# haltium_radiocore register map
Vendor: Nordic Semiconductor; Series: nRFHaltium; File version: 1
CPU: CM33 r0p4, little endian, MPU, FPU, 3 interrupt priority bits, 480 interrupts
Registers are 32-bit, read-write, reset 0x0 unless marked. A register's access mark holds for its fields unless they carry their own. Offsets are from the block's base; [hi:lo] are bit positions; lines under a group give offsets from that group; {n}, {i} and the like mark numbered series.

## PCGCM000_S — PCGC Master 0
Base 0x5300F000
Same registers: PCGCM010_S 0x5301F000, PCGCM020_S 0x5302F000, PCGCM030_S 0x5303F000
{0xE0+4i} SETPWRCONTHRESHOLDBASE[{i}] (i=0..2) — Description collection: Set power consumption threshold base for power source / regulator n
  [3:0] SETPWRCONTHRESHOLDBASE
{0x100+4i} SETPOWERCONSUMPTIONBASE[{i}] (i=0..1) — Description collection: Set power consumption base for power/clock pair n
  [3:0] POWERREQUIREMENT
0xC00 UNLOCKBACKDOORS
  [15:0] UNLOCKBACKDOORS — Write: 0x00009375 to lock/unlock backdoors Read: 0x00000001 if backdoors is enabled Read: 0x00000000 if backdoors is disabled
0xC04 ENABLEPOWERREGFORCE
  [2:0] ENABLEPOWERREGFORCE
0xC08 POWERREGFORCE — Force reg
  [2:0] POWERREGFORCEREG
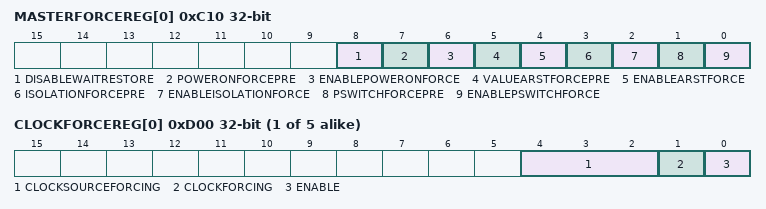
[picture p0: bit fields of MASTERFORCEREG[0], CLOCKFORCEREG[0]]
{0xC10+4i} MASTERFORCEREG[{i}] (i=0..0) — Description collection: Force reg
  [8] DISABLEWAITRESTORE — Turn off waiting for arst deactivation before retention restore
    1=Disable (Turn off waiting for arst deactivation before retention restore); 0=Enable (Wait for arst deactivation before retention restore)
  [7] POWERONFORCEPRE
  [6] ENABLEPOWERONFORCE
  [5] VALUEARSTFORCEPRE
  [4] ENABLEARSTFORCE
  [3] ISOLATIONFORCEPRE
  [2] ENABLEISOLATIONFORCE
  [1] PSWITCHFORCEPRE
  [0] ENABLEPSWITCHFORCE
{0xD00+4i} CLOCKFORCEREG[{i}] (i=0..4) — Description collection: Force clock n
  [4:2] CLOCKSOURCEFORCING
  [1] CLOCKFORCING
  [0] ENABLE — Enable clock forcing

## CPUCONF_NS — CPU Configuration 0
Base 0x43011000
Same registers: CPUCONF_S 0x53011000
0x00 TASKS_ERASECACHE wo — Erase the caches used by the CPU.
  [0] TASKS_ERASECACHE
    1=Trigger task
0x500 INITSVTOR — Initial value of the secure VTOR (Vector Table Offset Register) after CPU reset.
  [31:0] INITSVTOR — Initial value of the VTOR.
0x504 INITNSVTOR — Initial value of the non-secure VTOR (Vector Table Offset Register).
  [31:0] INITNSVTOR — Initial value of the VTOR.
0x508 CPUSTART — Enable for starting the CPU
  [0] EN — Enable to start the CPU.
    0=Stopped (CPU stopped.); 1=Started (CPU started.)
0x50C CPUWAIT — Enable for the CPU wait.
  [0] EN — Enable to the CPU wait.
    0=Disabled (CPU is not waiting.); 1=Enabled (CPU is waiting.)

## MEMCONF_NS — Memory configuration 0
Base 0x43012000
Same registers: MEMCONF_S 0x53012000
{0x500+0x10*i} POWER[{i}] (i=0..3) group — Unspecified
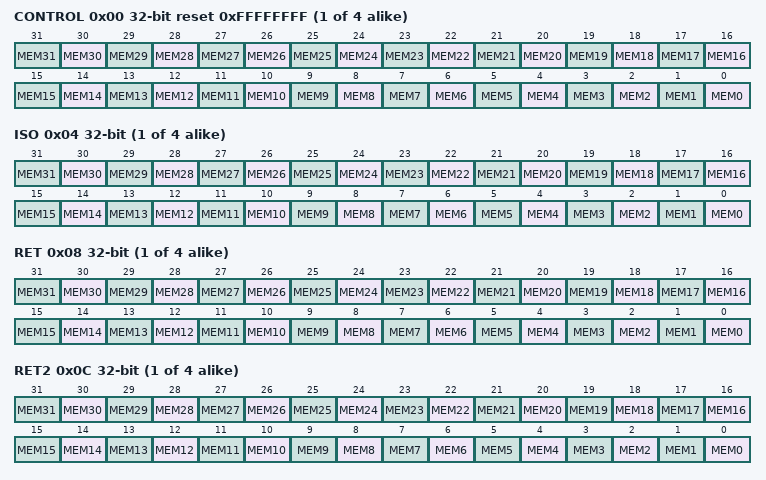
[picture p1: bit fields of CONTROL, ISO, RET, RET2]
  0x00 CONTROL reset 0xFFFFFFFF — Description cluster: RAM/ROM[n] power control register.
    [all] fields
      0=Off (Power down); 1=On (Power up)
    [n] MEM{n} (n=0..31) — Keep the RAM/ROM block MEM[{n}] on or off when in System ON mode.
  0x04 ISO — Description cluster: RAM/ROM [n] power isolation control register.
    [all] fields
      0=Off (Isolation off); 1=On (Isolation on)
    [n] MEM{n} (n=0..31) — Turn on/off the power isolation for RAM/ROM block MEM[{n}].
  0x08 RET — Description cluster: RAM retention for RAM/ROM [n].
    [all] fields
      0=Off (Retention off); 1=On (Retention on)
    [n] MEM{n} (n=0..31) — Keep the RAM block MEM[{n}] retained when in System OFF mode.
  0x0C RET2 — Description cluster: RAM retention for the second bank in the RAM block
    [all] fields
      0=Off (Retention off); 1=On (Retention on)
    [n] MEM{n} (n=0..31) — Keep the second bank in RAM block MEM[{n}] retained when in System OFF mode.
{0x600+4i} REPAIR[{i}] (i=0..191) group — Unspecified
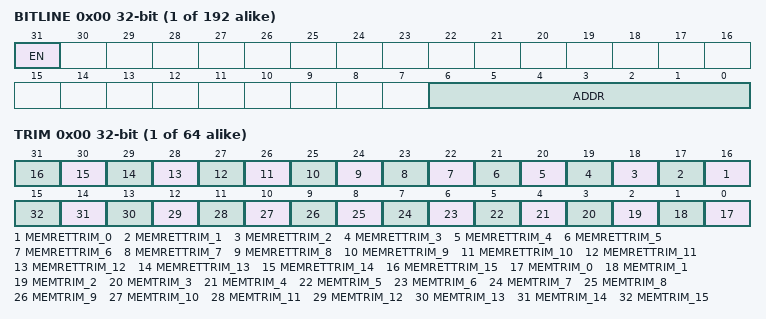
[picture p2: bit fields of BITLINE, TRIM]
  0x00 BITLINE — Description cluster: Repair configuration for RAM/ROM blocks.
    [31] EN — Enable bitline repair
      0=Disabled (Repair disabled.); 1=Enabled (Repair enabled.)
    [6:0] ADDR — Repair address of the bitline
{0x900+4i} BLOCKTYPE[{i}] (i=0..63) group — Unspecified
  0x00 TRIM — Description cluster: Trim configuration for the RAM/ROM block types.
    [n+16] MEMRETTRIM_{n} (n=0..15) — Trimming for retention mode for decreased leakage. Must be kept active in RAM retention mode.
    [n] MEMTRIM_{n} (n=0..15) — Read/write margin trim.
